# COMPUTE_CLUSTER_J7AHP0_GIC500SS_0_GIC_REDISTRIBUTOR_SGI_PPI_7 register map
Vendor: Texas Instruments
Peripheral module from a debugger description file (folder J7_AHP).
Registers are 32-bit, access not given, no defined reset value unless marked. A register's access mark holds for its fields unless they carry their own. Offsets are as the file gives them; lines under a group give offsets from that group; [hi:lo] are bit positions; {n}, {i} and the like mark numbered series; 'fields as' and 'values as' point back to an identical list; <NAME> marks a mode.

## COMPUTE_CLUSTER_J7AHP0_GIC500SS_0_GIC_REDISTRIBUTOR_SGI_PPI_7
0x80 GIC_REDISTRIBUTOR_SGI_PPI_7_Redistributor_SGI_PPI_7__1_GICR_IGROUPR0
0x100 GIC_REDISTRIBUTOR_SGI_PPI_7_Redistributor_SGI_PPI_7__2_GICR_ISENABLER0
0x180 GIC_REDISTRIBUTOR_SGI_PPI_7_Redistributor_SGI_PPI_7__3_GICR_ICENABLER0
0x200 GIC_REDISTRIBUTOR_SGI_PPI_7_Redistributor_SGI_PPI_7__4_GICR_ISPENDR0
0x280 GIC_REDISTRIBUTOR_SGI_PPI_7_Redistributor_SGI_PPI_7__5_GICR_ICPENDR0
0x300 GIC_REDISTRIBUTOR_SGI_PPI_7_Redistributor_SGI_PPI_7__6_GICR_ISACTIVER0
0x380 GIC_REDISTRIBUTOR_SGI_PPI_7_Redistributor_SGI_PPI_7__7_GICR_ICACTIVER0
{0x400+4i} GIC_REDISTRIBUTOR_SGI_PPI_7_Redistributor_SGI_PPI_7__8_GICR_IPRIORITYR{i} (i=0..7)
0xC00 GIC_REDISTRIBUTOR_SGI_PPI_7_Redistributor_SGI_PPI_7__9_GICR_ICFGR0
0xC04 GIC_REDISTRIBUTOR_SGI_PPI_7_Redistributor_SGI_PPI_7__10_GICR_ICFGR1
0xD00 GIC_REDISTRIBUTOR_SGI_PPI_7_Redistributor_SGI_PPI_7__11_GICR_IGRPMODR0
0xE00 GIC_REDISTRIBUTOR_SGI_PPI_7_Redistributor_SGI_PPI_7__12_GICR_NSACR
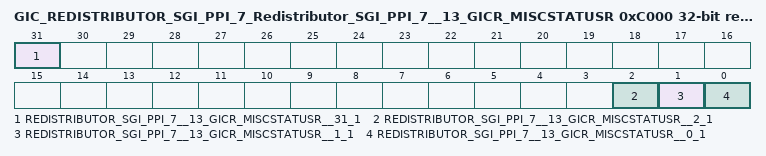
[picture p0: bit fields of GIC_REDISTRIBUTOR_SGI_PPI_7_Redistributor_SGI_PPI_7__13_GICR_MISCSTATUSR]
0xC000 GIC_REDISTRIBUTOR_SGI_PPI_7_Redistributor_SGI_PPI_7__13_GICR_MISCSTATUSR rw reset 0x0
  [31] REDISTRIBUTOR_SGI_PPI_7__13_GICR_MISCSTATUSR__31_1, [2] REDISTRIBUTOR_SGI_PPI_7__13_GICR_MISCSTATUSR__2_1, [1] REDISTRIBUTOR_SGI_PPI_7__13_GICR_MISCSTATUSR__1_1, [0] REDISTRIBUTOR_SGI_PPI_7__13_GICR_MISCSTATUSR__0_1
0xC080 GIC_REDISTRIBUTOR_SGI_PPI_7_Redistributor_SGI_PPI_7__14_GICR_PPISR rw reset 0x0
  [31:16] REDISTRIBUTOR_SGI_PPI_7__14_GICR_PPISR__16_16
